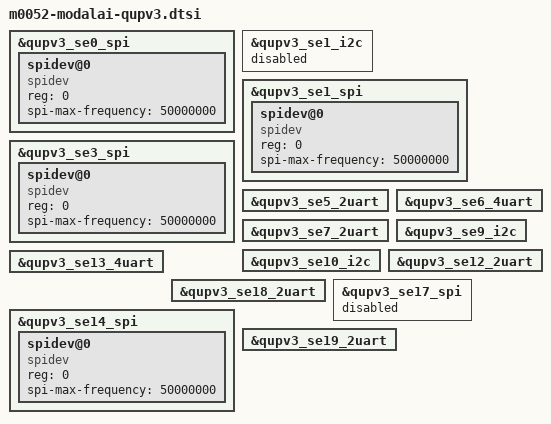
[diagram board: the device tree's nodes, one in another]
/* M0052 - J6 - Camera Group 0 - GPIO 28-31 */
&qupv3_se0_spi {
	status = "ok";
	spidev@0 {
		compatible = "spidev";
		reg = <0>;
		spi-max-frequency = <50000000>;
	};
};

/* M0052 - not used as I2C, exposed as Camera SPI */
&qupv3_se1_i2c {
	status = "disabled";
};

/* M0052 - J7 - Camera Group 1 - GPIO 4-7 */
&qupv3_se1_spi {
	status = "ok";
	spidev@0 {
		compatible = "spidev";
		reg = <0>;
		spi-max-frequency = <50000000>;
	};
};

/* M0052 - IMU1 - GPIO 119-122 */
&qupv3_se3_spi {
	status = "ok";
	spidev@0 {
		compatible = "spidev";
		reg = <0>;
		spi-max-frequency = <50000000>;
	};
};

/* M0054 - J8 - Camera Group 2 - GPIO 14-15 - /dev/ttyHS3 */
&qupv3_se5_2uart {
	status = "ok";
};

/* M0052 - SOM WiFi, GPIO 16-19 - /dev/ttyHS0 */
&qupv3_se6_4uart {
	status = "ok";
};

/* M0052 - J3 B2B pins 3/5 - /dev/ttyHS4 */
&qupv3_se7_2uart {
	status = "ok";
};

/* M0052 - B2B I2C - GPIO 125-126 */
&qupv3_se9_i2c {
	status = "ok";
};

/* M0052 - B2B I2C - GPIO 129-130 */
&qupv3_se10_i2c {
	status = "ok";
};

/* M0052 - Debug Console */
&qupv3_se12_2uart {
	status = "ok";
};

/* M0052 - RC Input - GPIO 38-39 - /dev/ttyHS1 */
&qupv3_se13_4uart {
	status = "ok";
};

/* M0052 - GNSS Input - GPIO 58-59 - /dev/ttyHS2 */
&qupv3_se18_2uart {
	status = "ok";
};

/* M0054 - J10 Pins 2-5 - GPIO 40-44 */
&qupv3_se14_spi {
	status = "ok";
	spidev@0 {
		compatible = "spidev";
		reg = <0>;
		spi-max-frequency = <50000000>;
	};
};

/* M0054 - J3 B2B, GPIO 52-55, used as GPIO */
&qupv3_se17_spi {
	status = "disabled";
};

/* HSB2B - External 2W UART, GPIO 2/3, HS B2B Pins 48/49 - /dev/ttyHS5 */
&qupv3_se19_2uart {
	status = "ok";
};
